# S6E2GMxH register map
Vendor: Cypress; File version: 2.1
CPU: CM4 r0p1, little endian, MPU, FPU, 4 interrupt priority bits
Registers are 32-bit, read-write, reset 0x0 unless marked. A register's access mark holds for its fields unless they carry their own. Offsets are from the block's base; [hi:lo] are bit positions; {n}, {i} and the like mark numbered series; 'fields as' and 'values as' point back to an identical list.

## CANPRES — CAN Prescaler Register
Base 0x40037000
0x00 CANPRE 8-bit reset 0xB — CAN Prescaler Register [BHW]
  [3:0] CANPRE — CAN prescaler setting bits

## CRC — CRC Registers
Base 0x40039000
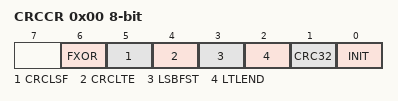
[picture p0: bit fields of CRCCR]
0x00 CRCCR 8-bit — CRC Control Register [BHW]
  [6] FXOR — Final XOR control bit
  [5] CRCLSF — CRC result bit-order setting bit
  [4] CRCLTE — CRC result byte-order setting bit
  [3] LSBFST — Bit-order setting bit
  [2] LTLEND — Byte-order setting bit
  [1] CRC32 — CRC mode selection bit
  [0] INIT — Initialization bit
0x04 CRCINIT reset 0xFFFFFFFF — Initial Value Register [BHW]
  [31:0] D — Initial value
0x08 CRCIN — Input Data Register [BHW]
  [31:0] D — Input data
0x0C CRCR ro reset 0xFFFFFFFF — CRC Register [BHW]
  [31:0] D — CRC Data

## WC — Watch Counter
Base 0x4003A000
0x00 WCRD 8-bit ro — Watch Counter Read Register [BHW]
  [5:0] CTR — Counter read bits
0x01 WCRL 8-bit — Watch Counter Reload Register [BHW]
  [5:0] RLC — Counter reload value setting bits
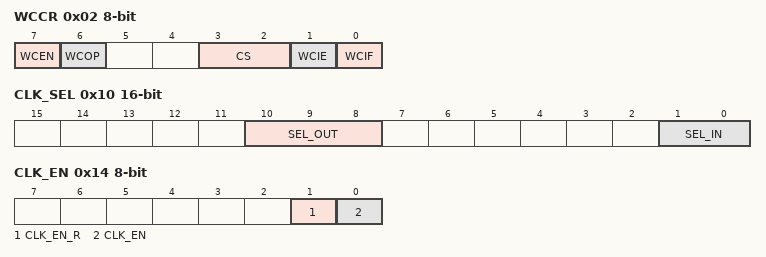
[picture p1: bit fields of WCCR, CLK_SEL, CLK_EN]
0x02 WCCR 8-bit — Watch Counter Control Register [BHW]
  [7] WCEN — Watch counter operation enable bit
  [6] WCOP ro — Watch counter operating state flag
  [3:2] CS — Count clock select bits
  [1] WCIE — Interrupt request enable bit
  [0] WCIF — Interrupt request flag bit
0x10 CLK_SEL 16-bit — Clock Selection Register [BHW]
  [10:8] SEL_OUT — Output clock selection bit
  [1:0] SEL_IN — Input clock selection bit
0x14 CLK_EN 8-bit — Division Clock Enable Register [BHW]
  [1] CLK_EN_R — Division clock enable read bit
  [0] CLK_EN — Division clock enable bit

## LSCRP — Low-speed CR Prescaler
Base 0x4003C000
0x00 LCR_PRSLD 8-bit — Low-speed CR Prescaler Control Register [BHW]
  [5:0] LCR_PRSLD — Low-speed CR Prescaler Load

## MFSI2SA — I2S0 Registers
Base 0x4003CA00
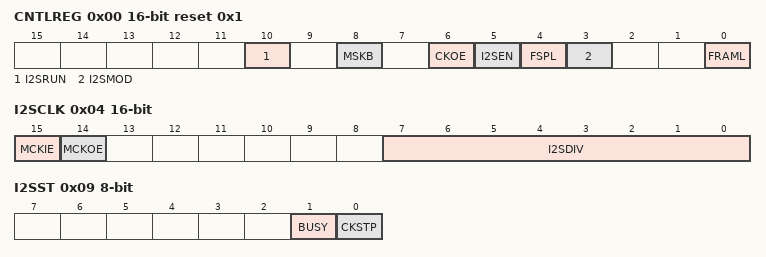
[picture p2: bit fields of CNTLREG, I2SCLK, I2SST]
0x00 CNTLREG 16-bit reset 0x1 — Control Register [BHW]
  [10] I2SRUN — I2S clock generate enable bit
  [8] MSKB — Mask bit output bit
  [6] CKOE — I2SCK and I2SWS output enable bit
  [5] I2SEN — I2S mode enable bit
  [4] FSPL — I2SWS polarity set bit
  [3] I2SMOD — I2S mode select bit
  [0] FRAML — Frame length select bit
0x04 I2SCLK 16-bit — I2S Clock Register [BHW]
  [15] MCKIE — Main clock input enable bit
  [14] MCKOE — Main clock output enable bit
  [7:0] I2SDIV — I2S clock division set bit
0x08 I2SRST 8-bit wo — I2S Reset Register [BHW]
  [7:0] I2SRST — I2S software reset bit
0x09 I2SST 8-bit ro — I2S Status Register [BHW]
  [1] BUSY — Bus busy indication for transmit bit
  [0] CKSTP — Clock stop indication bit

## DMAC — DMAC Registers
Base 0x40060000
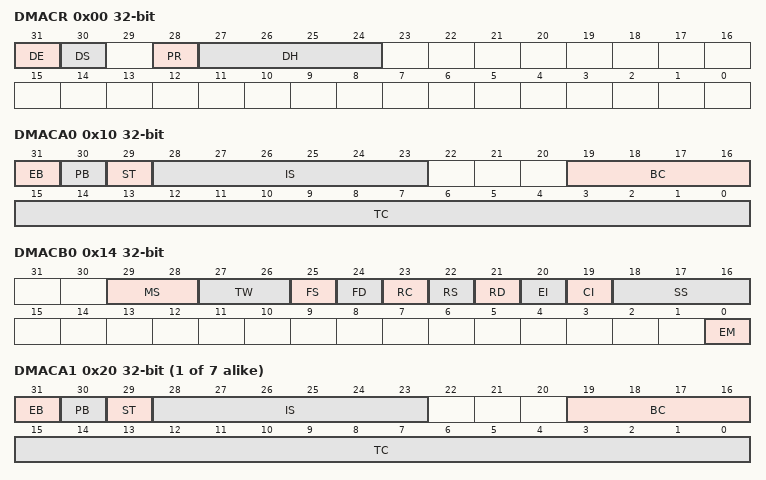
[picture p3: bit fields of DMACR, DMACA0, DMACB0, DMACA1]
0x00 DMACR — Entire DMAC Configuration Register [BHW]
  [31] DE — DMA Enable (all-channel operation enable bit)
  [30] DS — DMA Stop
  [28] PR — Priority Rotation
  [27:24] DH — DMA Halt (All-channel pause bit)
0x10 DMACA0 — Configuration A Register [BHW]
  [31] EB — Enable bit (individual-channel operation enable bit)
  [30] PB — Pause bit (individual-channel pause bit)
  [29] ST — Software Trigger
  [28:23] IS — Input Select
  [19:16] BC — Block Count
  [15:0] TC — Transfer Count
0x14 DMACB0 — Configuration B Register [BHW]
  [29:28] MS — Mode Select
  [27:26] TW — Transfer Width
  [25] FS — Fixed Source
  [24] FD — Fixed Destination
  [23] RC — Reload Count (BC/TC reload)
  [22] RS — Reload Source
  [21] RD — Reload Destination
  [20] EI — Error Interrupt (unsuccessful transfer completion interrupt enable)
  [19] CI — Completion Interrupt (successful transfer completion interrupt enable)
  [18:16] SS — Stop Status (stop status notification)
  [0] EM — Enable bit Mask (EB bit clear mask)
{0x18+0x10*i} DMACSA{i} (i=0..7) — Transfer Source Address Register {i} [BHW]
{0x1C+0x10*i} DMACDA{i} (i=0..7) — Transfer Destination Address Register {i} [BHW]
{0x10+0x10*i} DMACA{i} (i=1..7) — Configuration A Register {i} [BHW]
  fields as DMACA0
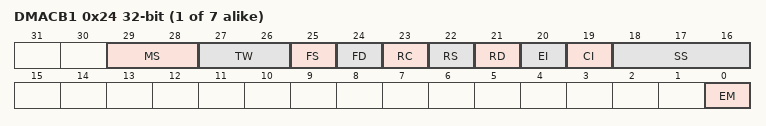
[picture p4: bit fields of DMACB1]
{0x14+0x10*i} DMACB{i} (i=1..7) — Configuration B Register {i} [BHW]
  fields as DMACB0

## DSTC — DSTC registers
Base 0x40061000
0x00 DESTP — Descriptor top address Register [BHW]
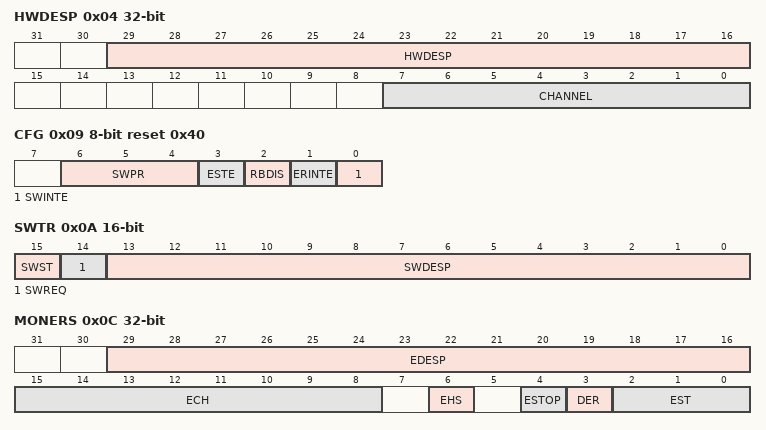
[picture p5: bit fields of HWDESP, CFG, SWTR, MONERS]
0x04 HWDESP — Hardware DES pointer Register [BHW]
  [29:16] HWDESP, [7:0] CHANNEL
0x08 CMD 8-bit reset 0x1 — Command Register [B]
0x09 CFG 8-bit reset 0x40 — Configuration Register [B]
  [6:4] SWPR — Software transfer priority
  [3] ESTE — Error stop enable
  [2] RBDIS — Read skip buffer disable
  [1] ERINTE — Error interrupt enable
  [0] SWINTE — Software interrupt enable
0x0A SWTR 16-bit — Software trigger Register [H]
  [15] SWST ro — Software status
  [14] SWREQ ro — Software request
  [13:0] SWDESP — Software DES pointer
0x0C MONERS ro — Transfer Error Status Monitor Register [BHW]
  [29:16] EDESP — Error DES pointer
  [15:8] ECH — Error hardware channel
  [6] EHS — Error hardware software
  [4] ESTOP — Error stop
  [3] DER — Double error
  [2:0] EST — Error status
{0x10+4i} DREQENB{i} (i=0..7) — DMA request enable Register {i} [BHW]
{0x30+4i} HWINT{i} ro (i=0..7) — Hardware transfer interrupt Register {i} [BHW]
{0x50+4i} HWINTCLR{i} wo (i=0..7) — Hardware transfer interrupt clear Register {i} [BHW]
{0x70+4i} DQMSK{i} ro (i=0..7) — DMA request mask Register {i} [BHW]
{0x90+4i} DQMSKCLR{i} wo (i=0..7) — DMA request mask clear Register {i} [BHW]

## ETHERNET_CONTROL — Ethernet system control
Base 0x40066000
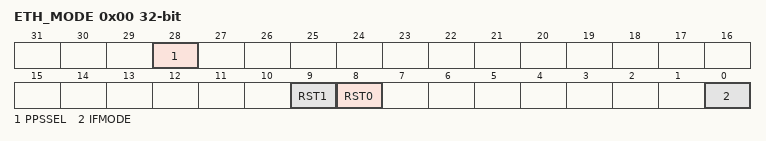
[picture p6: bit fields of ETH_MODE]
0x00 ETH_MODE — Mode Select Register [BHW]
  [28] PPSSEL — Select either of the system time counter pulse outputs of the Ethernet-MAC PTP function to output to E_PPS0_PPS1 pin
  [9] RST1 — reset signal against Ethernet-MAC (ch.1)
  [8] RST0 — reset signal against Ethernet-MAC (ch.0)
  [0] IFMODE — Mode selector
0x08 ETH_CLKG — Clock Gating Register [BHW]
  [1:0] MACEN — Select the system clock supply to Ethernet-MAC

## Notices in the file
Copyright (C) 2013-2016, Cypress Semiconductor Corporation or a
subsidiary of Cypress Semiconductor Corporation.  All rights reserved.
This software, including source code, documentation and related
materials ("Software"), is owned by Cypress Semiconductor Corporation or
one of its subsidiaries ("Cypress") and is protected by and subject to
worldwide patent protection (United States and foreign), United States
copyright laws and international treaty provisions. Therefore, you may use
this Software only as provided in the license agreement accompanying the
software package from which you obtained this Software ("EULA").
If no EULA applies, Cypress hereby grants you a personal, non-exclusive,
non-transferable license to copy, modify, and compile the
Software source code solely for use in connection with Cypress's
integrated circuit products.  Any reproduction, modification, translation,
compilation, or representation of this Software except as specified
above is prohibited without the express written permission of Cypress.
Disclaimer: THIS SOFTWARE IS PROVIDED AS-IS, WITH NO
WARRANTY OF ANY KIND, EXPRESS OR IMPLIED, INCLUDING,
BUT NOT LIMITED TO, NONINFRINGEMENT, IMPLIED
WARRANTIES OF MERCHANTABILITY AND FITNESS FOR A
PARTICULAR PURPOSE. Cypress reserves the right to make
changes to the Software without notice. Cypress does not assume any
liability arising out of the application or use of the Software or any
product or circuit described in the Software. Cypress does not
authorize its products for use in any products where a malfunction or
failure of the Cypress product may reasonably be expected to result in
significant property damage, injury or death ("High Risk Product"). By
including Cypress's product in a High Risk Product, the manufacturer
of such system or application assumes all risk of such use and in doing
so agrees to indemnify Cypress against all liability.
